# ATtiny26 register map
Vendor: Atmel; File version: 1.0
CPU: other r0p0, little endian, no MPU, no FPU, 4 interrupt priority bits
Registers are 8-bit, read-write, reset 0x0 unless marked. A register's access mark holds for its fields unless they carry their own. Offsets are from the block's base; [hi:lo] are bit positions; 'fields as' and 'values as' point back to an identical list.

## EXINT — External Interrupts
Base 0x0080005A
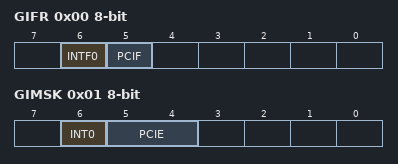
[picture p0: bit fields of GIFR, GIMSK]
0x00 GIFR — General Interrupt Flag register
  [6] INTF0 — External Interrupt Flag 0
  [5] PCIF — Pin Change Interrupt Flag
0x01 GIMSK — General Interrupt Mask Register
  [6] INT0 — External Interrupt Request 0 Enable
  [5:4] PCIE — Pin Change Interrupt Enables

## PORTA — I/O Port
Base 0x00800039
0x00 PINA — Port A Input Pins (read-only for debugger)
0x01 DDRA — Port A Data Direction Register
0x02 PORTA — Port A Data Register

## PORTB — I/O Port
Base 0x00800036
0x00 PINB — Port B Input Pins (read-only for debugger)
0x01 DDRB — Port B Data Direction Register
0x02 PORTB — Port B Data Register

## TC0 — Timer/Counter, 8-bit
Base 0x00800052
0x00 TCNT0 — Timer Counter 0
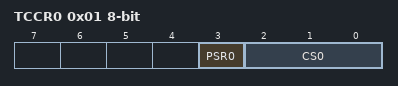
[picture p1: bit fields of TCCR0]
0x01 TCCR0 — Timer/Counter0 Control Register
  [3] PSR0 — Prescaler Reset Timer/Counter0
  [2:0] CS0 — Clock Select0 bits
    0=NO_CLOCK_SOURCE_STOPPED; 1=RUNNING_NO_PRESCALING; 2=RUNNING_CLK_8; 3=RUNNING_CLK_64; 4=RUNNING_CLK_256; 5=RUNNING_CLK_1024; 6=RUNNING_EXTCLK_TN_FALLING_EDGE; 7=RUNNING_EXTCLK_TN_RISING_EDGE
0x06 TIFR — Timer/Counter Interrupt Flag register
  [1] TOV0 — Timer/Counter0 Overflow Flag
0x07 TIMSK — Timer/Counter Interrupt Mask Register
  [1] TOIE0 — Timer/Counter0 Overflow Interrupt Enable

## TC1 — Timer/Counter, 8-bit
Base 0x00800049
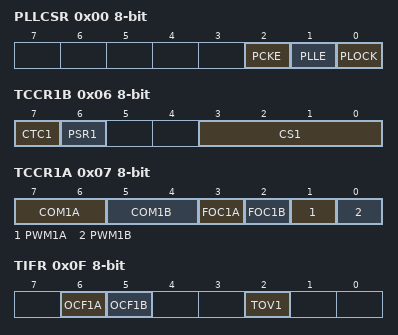
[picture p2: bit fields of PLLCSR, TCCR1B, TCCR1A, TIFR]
0x00 PLLCSR — PLL Control and Status Register
  [2] PCKE — PCK Enable
  [1] PLLE — PLL Enable
  [0] PLOCK — PLL Lock Detector
0x02 OCR1C — Output Compare Register
0x03 OCR1B — Output Compare Register
0x04 OCR1A — Output Compare Register
0x05 TCNT1 — Timer/Counter Register
0x06 TCCR1B — Timer/Counter Control Register B
  [7] CTC1 — Clear Timer/Counter on Compare Match
  [6] PSR1 — Prescaler Reset Timer/Counter1
  [3:0] CS1 — Clock Select Bits
    0=NO_CLOCK_SOURCE_STOPPED; 1=RUNNING_NO_PRESCALING; 2=RUNNING_CLK_2; 3=RUNNING_CLK_4; 4=RUNNING_CLK_8; 5=RUNNING_CLK_16; 6=RUNNING_CLK_32; 7=RUNNING_CLK_64; 8=RUNNING_CLK_128; 9=RUNNING_CLK_256; 10=RUNNING_CLK_512; 11=RUNNING_CLK_1024; 12=RUNNING_CLK_2048; 13=RUNNING_CLK_4096; 14=RUNNING_CLK_8192; 15=RUNNING_CLK_16384
0x07 TCCR1A — Timer/Counter Control Register A
  [7:6] COM1A — Comparator A Output Mode Bits
    0=DISCONNECTED_FROM_OCN_PWMN; 1=TOGGLE_OCN_PWMN_OUTPUT_LINE; 2=CLEAR_OCN_PWMN_OUTPUT_LINE; 3=SET_OCN_PWMN_OUTPUT_LINE
  [5:4] COM1B — Comparator B Output Mode Bits
    values as COM1A
  [3] FOC1A — Force Output Compare Match 1A
  [2] FOC1B — Force Output Compare Match 1B
  [1] PWM1A — Pulse Width Modulator A Enable
  [0] PWM1B — Pulse Width Modulator B Enable
0x0F TIFR — Timer/Counter Interrupt Flag Register
  [6] OCF1A — Timer/Counter1 Output Compare Flag 1A
  [5] OCF1B — Timer/Counter1 Output Compare Flag 1B
  [2] TOV1 — Timer/Counter1 Overflow Flag
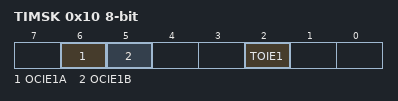
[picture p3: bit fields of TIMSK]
0x10 TIMSK — Timer/Counter Interrupt Mask Register
  [6] OCIE1A — Timer/Counter1 Output Compare Interrupt Enable
  [5] OCIE1B — Timer/Counter1 Output Compare Interrupt Enable
  [2] TOIE1 — Timer/Counter1 Overflow Interrupt Enable

## USI — Universal Serial Interface
Base 0x0080002D
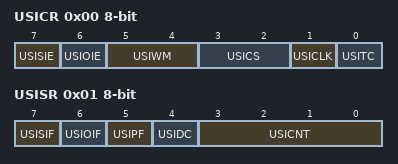
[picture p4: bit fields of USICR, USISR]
0x00 USICR — USI Control Register
  [7] USISIE — Start Condition Interrupt Enable
  [6] USIOIE — Counter Overflow Interrupt Enable
  [5:4] USIWM — USI Wire Mode Bits
    0=NORMAL_OPERATION; 1=THREE_WIRE_MODE; 2=TWO_WIRE_MODE; 3=TWO_WIRE_MODE_HELD_LOW
  [3:2] USICS — USI Clock Source Select Bits
  [1] USICLK — Clock Strobe
  [0] USITC — Toggle Clock Port Pin
0x01 USISR — USI Status Register (read-only for debugger)
  [7] USISIF — Start Condition Interrupt Flag
  [6] USIOIF — Counter Overflow Interrupt Flag
  [5] USIPF — Stop Condition Flag
  [4] USIDC — Data Output Collision
  [3:0] USICNT — USI Counter Value Bits
0x02 USIDR — USI Data Register

## WDT — Watchdog Timer
Base 0x00800041
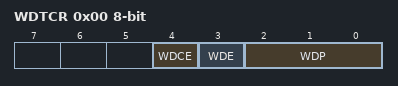
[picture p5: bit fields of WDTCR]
0x00 WDTCR — Watchdog Timer Control Register
  [4] WDCE — Watchdog Change Enable
  [3] WDE — Watch Dog Enable
  [2:0] WDP — Watch Dog Timer Prescaler bits
    0=OSCILLATOR_CYCLES_16K; 1=OSCILLATOR_CYCLES_32K; 2=OSCILLATOR_CYCLES_64K; 3=OSCILLATOR_CYCLES_128K; 4=OSCILLATOR_CYCLES_256K; 5=OSCILLATOR_CYCLES_512K; 6=OSCILLATOR_CYCLES_1024K; 7=OSCILLATOR_CYCLES_2048K
